# M4G7 register map
File version: 0.1
Registers are 32-bit, read-write, reset 0x0 unless marked. A register's access mark holds for its fields unless they carry their own. Offsets are from the block's base; [hi:lo] are bit positions; {n}, {i} and the like mark numbered series.

## CEC — Consumer Electronics Control (CEC)
Base 0x400E8000
0x00 EN — CEC Enable Register
  [0] CECEN
0x04 ADD — CEC Logical Address Register
  [15:0] CECADD
0x08 RESET wo — CEC Software Reset Register
  [0] CECRESET
0x0C REN (reset mask 0xFFFFFFFE) — CEC Receive Enable Register
  [0] CECREN
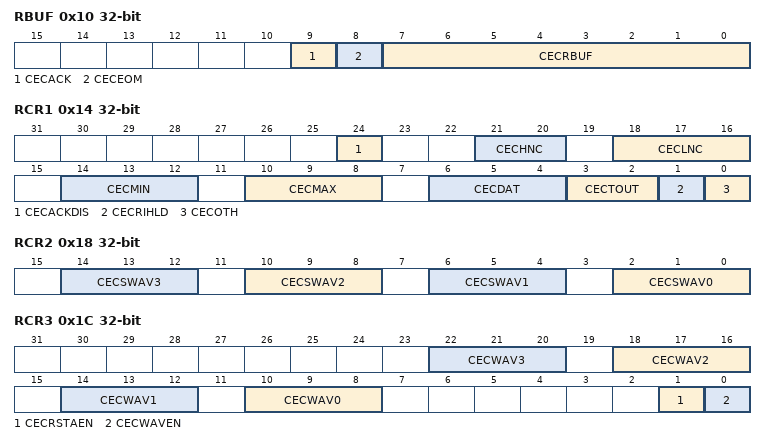
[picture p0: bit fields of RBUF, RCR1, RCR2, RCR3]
0x10 RBUF ro — CEC Receive Buffer Register
  [9] CECACK, [8] CECEOM, [7:0] CECRBUF
0x14 RCR1 — CEC Receive Control Register 1
  [24] CECACKDIS, [21:20] CECHNC, [18:16] CECLNC, [14:12] CECMIN, [10:8] CECMAX, [6:4] CECDAT, [3:2] CECTOUT, [1] CECRIHLD, [0] CECOTH
0x18 RCR2 — CEC Receive Control Register 2
  [4n+2:4n] CECSWAV{n} (n=0..3)
0x1C RCR3 — CEC Receive Control Register 3
  [4n+10:4n+8] CECWAV{n} (n=0..3), [1] CECRSTAEN, [0] CECWAVEN
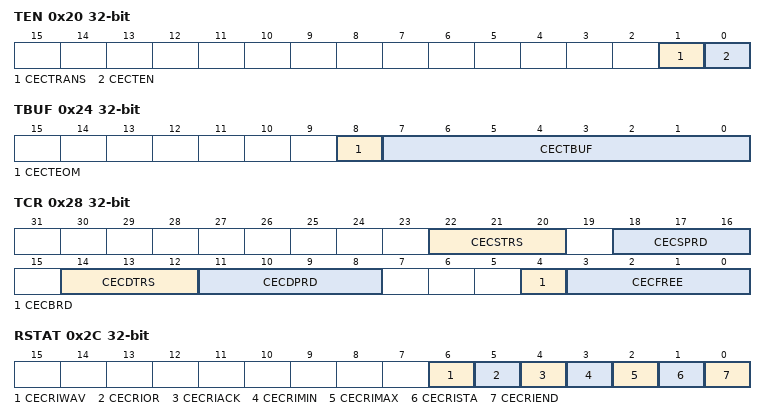
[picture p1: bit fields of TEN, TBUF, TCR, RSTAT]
0x20 TEN (reset mask 0xFFFFFFFE) — CEC Transmit Enable Register
  [1] CECTRANS ro, [0] CECTEN wo
0x24 TBUF — CEC Transmit Buffer Register
  [8] CECTEOM, [7:0] CECTBUF
0x28 TCR — CEC Transmit Control Register
  [22:20] CECSTRS, [18:16] CECSPRD, [14:12] CECDTRS, [11:8] CECDPRD, [4] CECBRD, [3:0] CECFREE
0x2C RSTAT ro — CEC Receive Interrupt Status Register
  [6] CECRIWAV, [5] CECRIOR, [4] CECRIACK, [3] CECRIMIN, [2] CECRIMAX, [1] CECRISTA, [0] CECRIEND
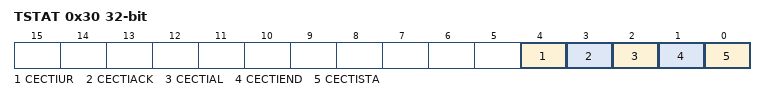
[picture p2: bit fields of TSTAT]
0x30 TSTAT ro — CEC Transmit Interrupt Status Register
  [4] CECTIUR, [3] CECTIACK, [2] CECTIAL, [1] CECTIEND, [0] CECTISTA
0x34 FSSEL — CEC sampling clock selection Register
  [0] CECCLK

## RMC0 — Remote Control Signal Preprocessor (RMC)
Base 0x400E8100
Same registers: RMC1 0x400E8200
0x00 EN — RMC Enable Register
  [0] RMCEN
0x04 REN — RMC Receive Enable Register
  [0] RMCREN
0x08 RBUF1 ro — RMC Receive Data Buffer Register 1
  [31:0] RMCRBUF
0x0C RBUF2 ro — RMC Receive Data Buffer Register 2
  [31:0] RMCRBUF
0x10 RBUF3 ro — RMC Receive Data Buffer Register 3
  [7:0] RMCRBUF
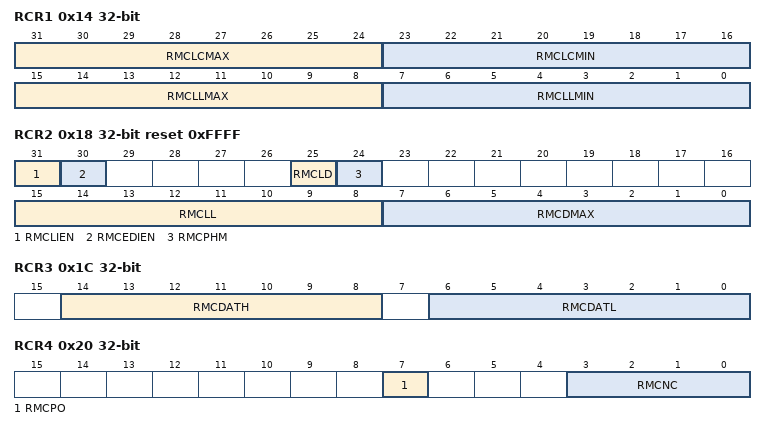
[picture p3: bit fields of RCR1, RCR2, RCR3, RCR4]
0x14 RCR1 — RMC Receive Control Register 1
  [31:24] RMCLCMAX, [23:16] RMCLCMIN, [15:8] RMCLLMAX, [7:0] RMCLLMIN
0x18 RCR2 reset 0xFFFF — RMC Receive Control Register 2
  [31] RMCLIEN, [30] RMCEDIEN, [25] RMCLD, [24] RMCPHM, [15:8] RMCLL, [7:0] RMCDMAX
0x1C RCR3 — RMC Receive Control Register 3
  [14:8] RMCDATH, [6:0] RMCDATL
0x20 RCR4 — RMC Receive Control Register 4
  [7] RMCPO, [3:0] RMCNC
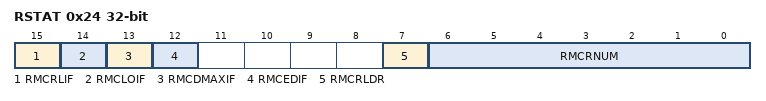
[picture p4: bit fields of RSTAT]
0x24 RSTAT ro — RMC Receive Status Register
  [15] RMCRLIF, [14] RMCLOIF, [13] RMCDMAXIF, [12] RMCEDIF, [7] RMCRLDR, [6:0] RMCRNUM
{0x24+4i} END{i} (i=1..3) — RMC Receive End Bit Number Register {i}
  [6:0] RMCEND{i}
0x34 FSSEL — RMC Frequency Selection Register
  [0] RMCCLK

## PMD
Base 0x400E9000
0x00 MDEN — PMD Enable Register
  [0] PWMEN
0x04 PORTMD — PMD Port Output Mode Register
  [1:0] PORTMD
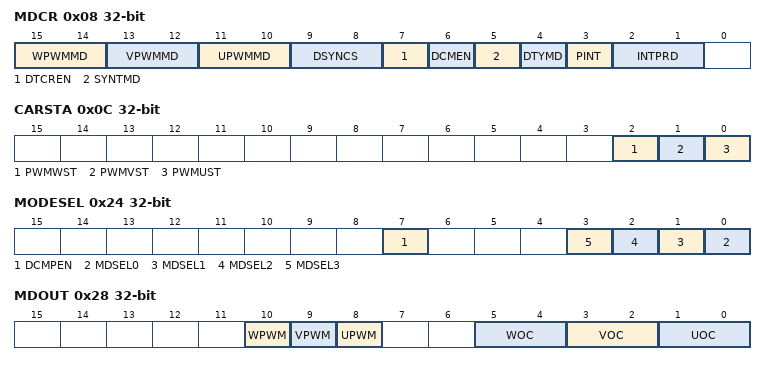
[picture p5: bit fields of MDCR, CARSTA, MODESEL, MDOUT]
0x08 MDCR — PMD Control Register
  [15:14] WPWMMD, [13:12] VPWMMD, [11:10] UPWMMD, [9:8] DSYNCS, [7] DTCREN, [6] DCMEN, [5] SYNTMD, [4] DTYMD, [3] PINT, [2:1] INTPRD
0x0C CARSTA ro — PWM Carrier Status Register
  [2] PWMWST, [1] PWMVST, [0] PWMUST
0x10 BCARI ro — PWM Basic Carrier Register
  [14:0] BCARI
0x14 RATE — PWM Frequency Register
  [14:0] RATE
0x18 CMPU — PMD PWM Compare U Register
  [15:0] CMPU
0x1C CMPV — PMD PWM Compare V Register
  [15:0] CMPV
0x20 CMPW — PMD PWM Compare W Register
  [15:0] CMPW
0x24 MODESEL — PMD Mode Select Register
  [7] DCMPEN, [n] MDSEL{n} (n=0..3)
0x28 MDOUT — PMD Conduction Control Register
  [10] WPWM, [9] VPWM, [8] UPWM, [5:4] WOC, [3:2] VOC, [1:0] UOC
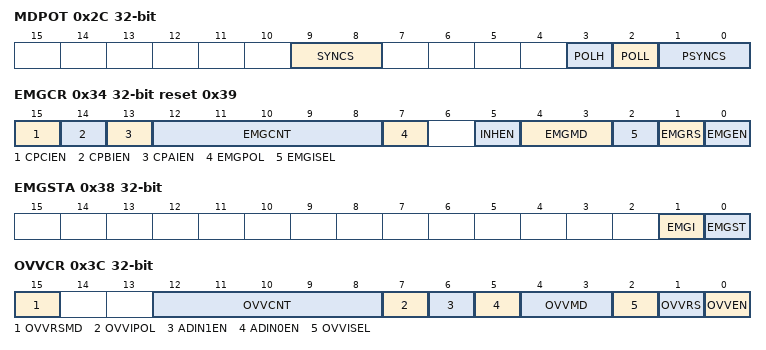
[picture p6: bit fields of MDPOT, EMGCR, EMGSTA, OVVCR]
0x2C MDPOT — PMD Output Setting Register
  [9:8] SYNCS, [3] POLH, [2] POLL, [1:0] PSYNCS
0x30 EMGREL wo — PMD EMG Release Register
  [7:0] EMGREL
0x34 EMGCR reset 0x39 — PMD EMG Control Register
  [15] CPCIEN, [14] CPBIEN, [13] CPAIEN, [12:8] EMGCNT, [7] EMGPOL, [5] INHEN, [4:3] EMGMD, [2] EMGISEL, [1] EMGRS wo, [0] EMGEN
0x38 EMGSTA ro (reset mask 0xFFFFFFFD) — PMD EMG Status Register
  [1] EMGI, [0] EMGST
0x3C OVVCR — PMD OVV Control Register
  [15] OVVRSMD, [12:8] OVVCNT, [7] OVVIPOL ro, [6] ADIN1EN, [5] ADIN0EN, [4:3] OVVMD, [2] OVVISEL, [1] OVVRS, [0] OVVEN
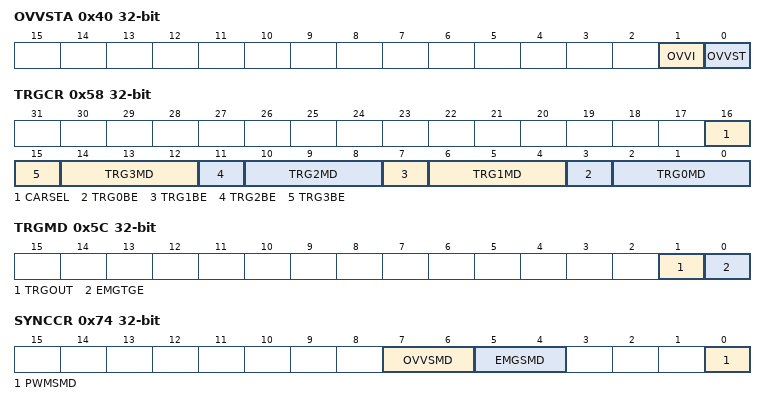
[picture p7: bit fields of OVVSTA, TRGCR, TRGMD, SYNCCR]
0x40 OVVSTA ro (reset mask 0xFFFFFFFD) — PMD OVV Status Register
  [1] OVVI, [0] OVVST
0x44 DTR — PMD Dead Time Register
  [9:0] DTR
{0x48+4i} TRGCMP{i} (i=0..3) — PMD Trigger Compare Register {i}
  [14:0] TRGCMP{i}
0x58 TRGCR — PMD Trigger Control Register
  [16] CARSEL, [4n+3] TRG{n}BE (n=0..3), [4n+2:4n] TRG{n}MD (n=0..3)
0x5C TRGMD — PMD Trigger Output Mode Setting Register
  [1] TRGOUT, [0] EMGTGE
0x60 TRGSEL — PMD Trigger Output Select Register
  [2:0] TRGSEL
0x64 TRGSYNCR — PMD Trigger Update Timing Setting Register
  [1:0] TSYNCS
0x68 VPWMPH — Phase difference setting of the V-phase PWM
  [14:0] VPWMPH
0x6C WPWMPH — Phase difference setting of the W-phase PWM
  [14:0] WPWMPH
0x70 MBUFCR — Update timing of the triple buffer
  [2:0] BUFCTR
0x74 SYNCCR — Synchronization control between the PMD channel
  [7:6] OVVSMD, [5:4] EMGSMD, [0] PWMSMD
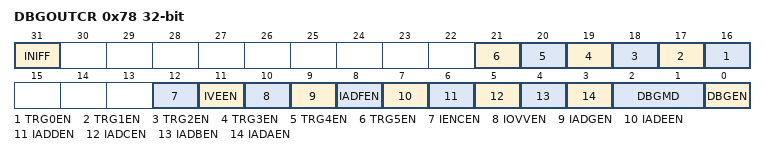
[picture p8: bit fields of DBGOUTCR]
0x78 DBGOUTCR — Debug output control
  [31] INIFF, [n+16] TRG{n}EN (n=0..5), [12] IENCEN, [11] IVEEN, [10] IOVVEN, [9] IADGEN, [8] IADFEN, [7] IADEEN, [6] IADDEN, [5] IADCEN, [4] IADBEN, [3] IADAEN, [2:1] DBGMD, [0] DBGEN

## SDA — SD
Base 0x400F0000
Same registers: SDB 0x400F0100, SDC 0x400F0200
0x00 EN — Interval Sencing Detector(ISD)
  [0] EN
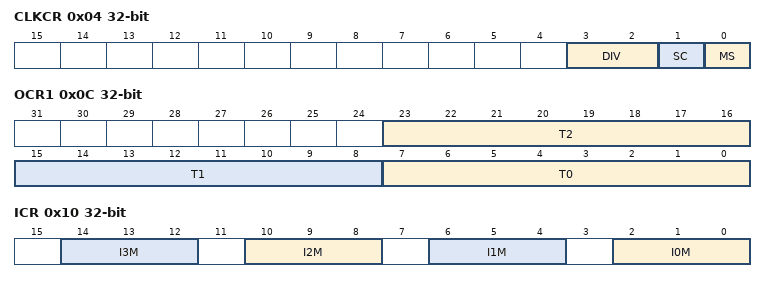
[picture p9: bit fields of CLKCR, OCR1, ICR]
0x04 CLKCR — Clock Control Register
  [3:2] DIV, [1] SC, [0] MS
0x08 OCR0 — Output Control Register 0
  [0] SDOP
0x0C OCR1 — Output Control Register 1
  [23:16] T2, [15:8] T1, [7:0] T0
0x10 ICR — Input Control Register
  [4n+2:4n] I{n}M (n=0..3)
0x14 CR — Control Register
  [0] START
0x18 BR ro — Buffer Register
  [3:0] B0
0x1C SR ro — Status Register
  [3:0] S0
0x20 INTCR ro — Interrupu Control Register
  [0] INTEN

## FC
Base 0x5DFF0000
0x10 SBMR reset 0x1 — Flash Security Bit Mask Register
  [0] SMB
0x14 SSR reset 0xFFFFFFFFFFFFFFFF — Flash Security Status Register
  [0] SEC ro
0x18 KCR wo — Flash Key Code Register
  [31:0] KEYCODE
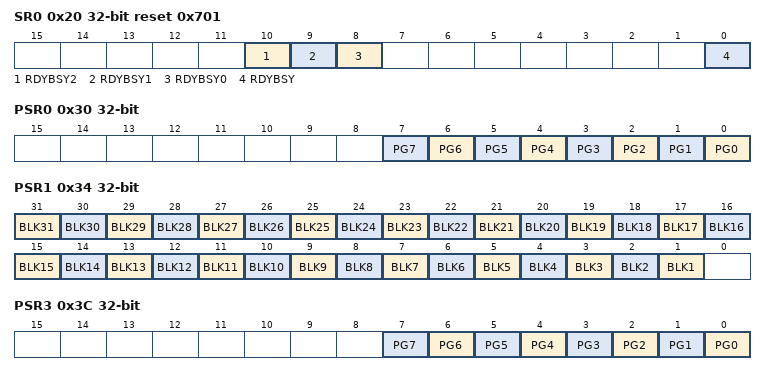
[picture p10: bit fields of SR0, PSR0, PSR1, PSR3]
0x20 SR0 reset 0x701 — Flash Status Register 0
  [10] RDYBSY2 ro, [9] RDYBSY1 ro, [8] RDYBSY0 ro, [0] RDYBSY ro
0x30 PSR0 ro (reset mask 0xFFFFFF00) — Flash Protect Status Register 0
  [n] PG{n} (n=0..7)
0x34 PSR1 ro (reset mask 0x1) — Flash Protect Status Register 1
  [n] BLK{n} (n=1..31)
0x3C PSR3 ro (reset mask 0xFFFFFF00) — Flash Protect Status Register 3
  [n] PG{n} (n=0..7)
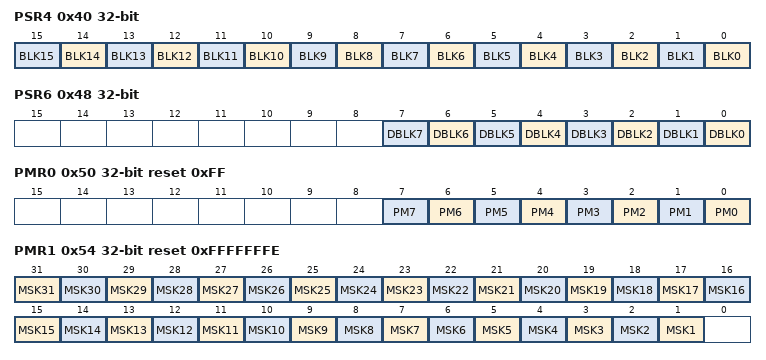
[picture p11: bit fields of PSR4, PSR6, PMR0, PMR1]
0x40 PSR4 ro (reset mask 0xFFFF0000) — Flash Protect Status Register 4
  [n] BLK{n} (n=0..15)
0x48 PSR6 ro (reset mask 0xFFFFFF00) — Flash Protect Status Register 6
  [n] DBLK{n} (n=0..7)
0x50 PMR0 reset 0xFF — Flash Protect Mask Register 0
  [n] PM{n} (n=0..7)
0x54 PMR1 reset 0xFFFFFFFE — Flash Protect Mask Register 1
  [n] MSK{n} (n=1..31)
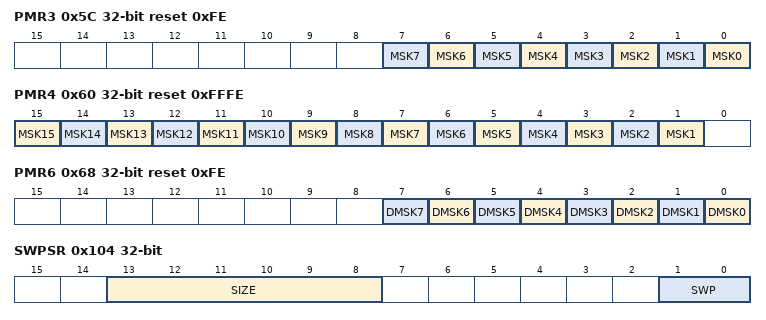
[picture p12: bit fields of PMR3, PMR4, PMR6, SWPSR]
0x5C PMR3 reset 0xFE — Flash Protect Mask Register 3
  [n] MSK{n} (n=0..7)
0x60 PMR4 reset 0xFFFE — Flash Protect Mask Register 4
  [n] MSK{n} (n=1..15)
0x68 PMR6 reset 0xFE — Flash Protect Mask Register 6
  [n] DMSK{n} (n=0..7)
0x100 SR1 ro — Flash Status Register 1
  [24] WEABORT
0x104 SWPSR ro — Flash Memory SWP Status Register
  [13:8] SIZE, [1:0] SWP
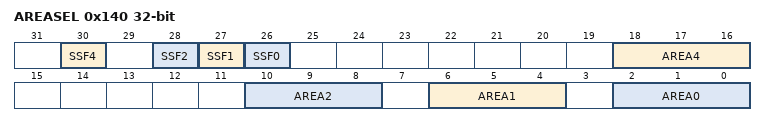
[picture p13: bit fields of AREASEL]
0x140 AREASEL — Flash Area Selection Register
  [30] SSF4 ro, [28] SSF2 ro, [27] SSF1 ro, [26] SSF0 ro, [18:16] AREA4, [10:8] AREA2, [6:4] AREA1, [2:0] AREA0
0x148 CR — Flash Control Register
  [2:0] WEABORT
0x14C STSCLR — Flash Status Clear Register
  [2:0] WEABORT
0x150 BNKCR — Flash Bank Change Register
  [2:0] BANK0
0x158 BUFDISCLR — Flash Buffer Disable and Clear Register
  [2:0] BUFDISCLR
